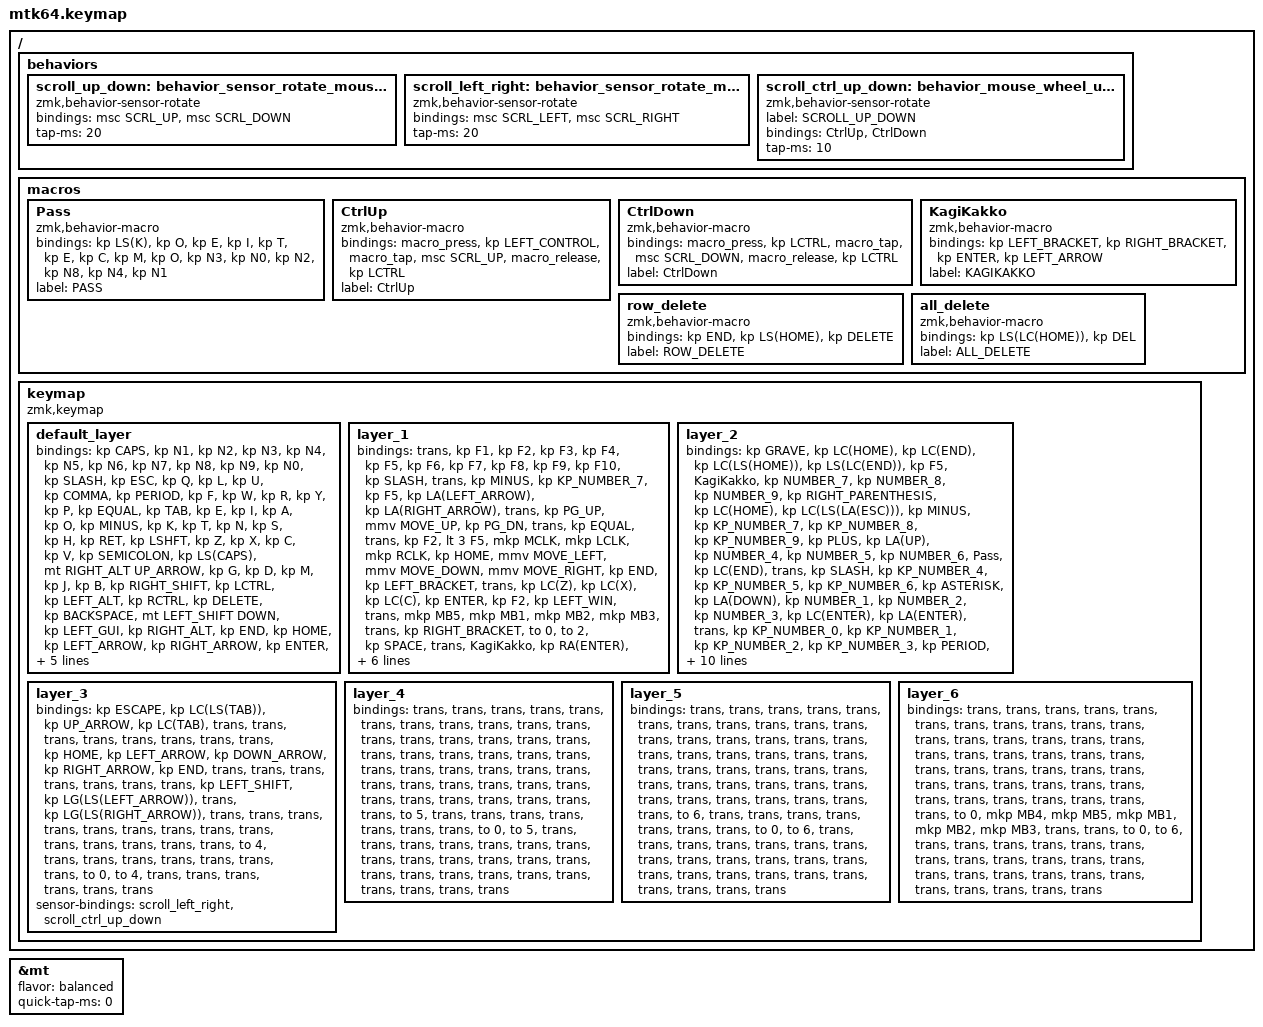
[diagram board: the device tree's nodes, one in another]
#include "keycode_japanese.h"
#include <behaviors.dtsi>
#include <dt-bindings/zmk/keys.h>
#include <dt-bindings/zmk/pointing.h>

// スクロール量の設定

#define ZMK_POINTING_DEFAULT_SCRL_VAL 100

&mt {
    flavor = "balanced";
    quick-tap-ms = <0>;
};

/ {
    behaviors {
        // 垂直スクロール用のbehaviorの設定

        scroll_up_down: behavior_sensor_rotate_mouse_wheel_up_down {
            compatible = "zmk,behavior-sensor-rotate";
            #sensor-binding-cells = <0>;
            bindings = <&msc SCRL_UP>, <&msc SCRL_DOWN>;

            tap-ms = <20>; // スクロールのタップ時間
        };

        // 水平スクロール用のbehaviorの設定

        scroll_left_right: behavior_sensor_rotate_mouse_wheel_left_right {
            compatible = "zmk,behavior-sensor-rotate";
            #sensor-binding-cells = <0>;
            bindings = <&msc SCRL_LEFT>, <&msc SCRL_RIGHT>;

            tap-ms = <20>; // スクロールのタップ時間
        };

        scroll_ctrl_up_down: behavior_mouse_wheel_up_down {
            compatible = "zmk,behavior-sensor-rotate";
            label = "SCROLL_UP_DOWN";
            #sensor-binding-cells = <0>;
            bindings = <&CtrlUp>, <&CtrlDown>;

            tap-ms = <10>;
        };
    };
};

/ {
    macros {
        Pass: Pass {
            compatible = "zmk,behavior-macro";
            #binding-cells = <0>;
            bindings = <&kp LS(K) &kp O &kp E &kp I &kp T &kp E &kp C &kp M &kp O &kp N3 &kp N0 &kp N2 &kp N8 &kp N4 &kp N1>;
            label = "PASS";
        };

        CtrlUp: CtrlUp {
            compatible = "zmk,behavior-macro";
            #binding-cells = <0>;
            bindings =
                <&macro_press>,
                <&kp LEFT_CONTROL>,
                <&macro_tap>,
                <&msc SCRL_UP>,
                <&macro_release>,
                <&kp LCTRL>;

            label = "CtrlUp";
        };

        CtrlDown: CtrlDown {
            compatible = "zmk,behavior-macro";
            #binding-cells = <0>;
            bindings =
                <&macro_press>,
                <&kp LCTRL>,
                <&macro_tap>,
                <&msc SCRL_DOWN>,
                <&macro_release>,
                <&kp LCTRL>;

            label = "CtrlDown";
        };

        KagiKakko: KagiKakko {
            compatible = "zmk,behavior-macro";
            #binding-cells = <0>;
            bindings = <&kp LEFT_BRACKET &kp RIGHT_BRACKET &kp ENTER &kp LEFT_ARROW>;
            label = "KAGIKAKKO";
        };

        row_delete: row_delete {
            compatible = "zmk,behavior-macro";
            #binding-cells = <0>;
            bindings = <&kp END &kp LS(HOME) &kp DELETE>;
            label = "ROW_DELETE";
        };

        all_delete: all_delete {
            compatible = "zmk,behavior-macro";
            #binding-cells = <0>;
            bindings = <&kp LS(LC(HOME)) &kp DEL>;
            label = "ALL_DELETE";
        };
    };

    keymap {
        compatible = "zmk,keymap";

        default_layer {
            bindings = <
&kp CAPS  &kp N1  &kp N2  &kp N3  &kp N4  &kp N5  &kp N6  &kp N7  &kp N8  &kp N9  &kp N0  &kp SLASH  &kp ESC  &kp Q  &kp L  &kp U  &kp COMMA  &kp PERIOD  &kp F  &kp W  &kp R  &kp Y  &kp P  &kp EQUAL  &kp TAB  &kp E  &kp I  &kp A  &kp O  &kp MINUS  &kp K  &kp T  &kp N  &kp S  &kp H  &kp RET  &kp LSHFT  &kp Z  &kp X  &kp C  &kp V  &kp SEMICOLON  &kp LS(CAPS)  &mt RIGHT_ALT UP_ARROW  &kp G  &kp D  &kp M  &kp J  &kp B  &kp RIGHT_SHIFT  &kp LCTRL  &kp LEFT_ALT  &kp RCTRL  &kp DELETE  &kp BACKSPACE  &mt LEFT_SHIFT DOWN  &kp LEFT_GUI  &kp RIGHT_ALT  &kp END  &kp HOME  &kp LEFT_ARROW  &kp RIGHT_ARROW  &kp ENTER  &tog 2  &lt 1 SPACE  &lt 2 BACKSPACE  &mo 1  &mo 2  &mo 3  &mo 1  &mo 2  &mo 3  &mo 1  &mo 2  &mo 3
            >;

            sensor-bindings = <&scroll_left_right>, <&scroll_up_down>;
        };

        layer_1 {
            bindings = <
&trans  &kp F1  &kp F2  &kp F3  &kp F4  &kp F5  &kp F6  &kp F7  &kp F8  &kp F9  &kp F10  &kp SLASH  &trans  &kp MINUS  &kp KP_NUMBER_7  &kp F5  &kp LA(LEFT_ARROW)  &kp LA(RIGHT_ARROW)  &trans  &kp PG_UP  &mmv MOVE_UP  &kp PG_DN  &trans  &kp EQUAL  &trans  &kp F2  &lt 3 F5  &mkp MCLK  &mkp LCLK  &mkp RCLK  &kp HOME  &mmv MOVE_LEFT  &mmv MOVE_DOWN  &mmv MOVE_RIGHT  &kp END  &kp LEFT_BRACKET  &trans  &kp LC(Z)  &kp LC(X)  &kp LC(C)  &kp ENTER  &kp F2  &kp LEFT_WIN  &trans  &mkp MB5  &mkp MB1  &mkp MB2  &mkp MB3  &trans  &kp RIGHT_BRACKET  &to 0  &to 2  &kp SPACE  &trans  &KagiKakko  &kp RA(ENTER)  &kp SQT  &kp BACKSLASH  &trans  &trans  &kp HOME  &kp END  &trans  &trans  &trans  &kp BACKSPACE  &trans  &trans  &trans  &trans  &trans  &trans  &trans  &trans  &trans
            >;

            sensor-bindings = <&inc_dec_kp D S>, <&scroll_ctrl_up_down>;
        };

        layer_2 {
            bindings = <
&kp GRAVE  &kp LC(HOME)  &kp LC(END)  &kp LC(LS(HOME))  &kp LS(LC(END))  &kp F5  &KagiKakko  &kp NUMBER_7  &kp NUMBER_8  &kp NUMBER_9  &kp RIGHT_PARENTHESIS  &kp LC(HOME)  &kp LC(LS(LA(ESC)))  &kp MINUS  &kp KP_NUMBER_7  &kp KP_NUMBER_8  &kp KP_NUMBER_9  &kp PLUS  &kp LA(UP)  &kp NUMBER_4  &kp NUMBER_5  &kp NUMBER_6  &Pass  &kp LC(END)  &trans  &kp SLASH  &kp KP_NUMBER_4  &kp KP_NUMBER_5  &kp KP_NUMBER_6  &kp ASTERISK  &kp LA(DOWN)  &kp NUMBER_1  &kp NUMBER_2  &kp NUMBER_3  &kp LC(ENTER)  &kp LA(ENTER)  &trans  &kp KP_NUMBER_0  &kp KP_NUMBER_1  &kp KP_NUMBER_2  &kp KP_NUMBER_3  &kp PERIOD  &to 3  &trans  &kp F4  &kp NUMBER_0  &mkp MB2  &mkp MB3  &trans  &kp LC(LS(HOME))  &to 0  &to 3  &all_delete  &row_delete  &trans  &trans  &kp APOS  &kp LC(LS(END))  &trans  &kp F2  &kp HOME  &kp END  &trans  &trans  &kp LEFT_SHIFT  &trans  &trans  &trans  &trans  &trans  &trans  &trans  &trans  &trans  &trans
            >;

            sensor-bindings =
                <&inc_dec_kp LEFT_ARROW RIGHT_ARROW>,
                <&inc_dec_kp UP_ARROW DOWN_ARROW>;
        };

        layer_3 {
            bindings = <
&kp ESCAPE  &kp LC(LS(TAB))  &kp UP_ARROW  &kp LC(TAB)  &trans  &trans  &trans  &trans  &trans  &trans  &trans  &trans  &kp HOME  &kp LEFT_ARROW  &kp DOWN_ARROW  &kp RIGHT_ARROW  &kp END  &trans  &trans  &trans  &trans  &trans  &trans  &trans  &kp LEFT_SHIFT  &kp LG(LS(LEFT_ARROW))  &trans  &kp LG(LS(RIGHT_ARROW))  &trans  &trans  &trans  &trans  &trans  &trans  &trans  &trans  &trans  &trans  &trans  &trans  &trans  &trans  &to 4  &trans  &trans  &trans  &trans  &trans  &trans  &trans  &to 0  &to 4  &trans  &trans  &trans  &trans  &trans  &trans
            >;

            sensor-bindings = <&scroll_left_right>, <&scroll_ctrl_up_down>;
        };

        layer_4 {
            bindings = <
&trans  &trans  &trans  &trans  &trans  &trans  &trans  &trans  &trans  &trans  &trans  &trans  &trans  &trans  &trans  &trans  &trans  &trans  &trans  &trans  &trans  &trans  &trans  &trans  &trans  &trans  &trans  &trans  &trans  &trans  &trans  &trans  &trans  &trans  &trans  &trans  &trans  &trans  &trans  &trans  &trans  &trans  &to 5  &trans  &trans  &trans  &trans  &trans  &trans  &trans  &to 0  &to 5  &trans  &trans  &trans  &trans  &trans  &trans  &trans  &trans  &trans  &trans  &trans  &trans  &trans  &trans  &trans  &trans  &trans  &trans  &trans  &trans  &trans  &trans  &trans
            >;
        };

        layer_5 {
            bindings = <
&trans  &trans  &trans  &trans  &trans  &trans  &trans  &trans  &trans  &trans  &trans  &trans  &trans  &trans  &trans  &trans  &trans  &trans  &trans  &trans  &trans  &trans  &trans  &trans  &trans  &trans  &trans  &trans  &trans  &trans  &trans  &trans  &trans  &trans  &trans  &trans  &trans  &trans  &trans  &trans  &trans  &trans  &to 6  &trans  &trans  &trans  &trans  &trans  &trans  &trans  &to 0  &to 6  &trans  &trans  &trans  &trans  &trans  &trans  &trans  &trans  &trans  &trans  &trans  &trans  &trans  &trans  &trans  &trans  &trans  &trans  &trans  &trans  &trans  &trans  &trans
            >;
        };

        layer_6 {
            bindings = <
&trans  &trans  &trans  &trans  &trans  &trans  &trans  &trans  &trans  &trans  &trans  &trans  &trans  &trans  &trans  &trans  &trans  &trans  &trans  &trans  &trans  &trans  &trans  &trans  &trans  &trans  &trans  &trans  &trans  &trans  &trans  &trans  &trans  &trans  &trans  &trans  &trans  &trans  &trans  &trans  &trans  &trans  &to 0  &mkp MB4  &mkp MB5  &mkp MB1  &mkp MB2  &mkp MB3  &trans  &trans  &to 0  &to 6  &trans  &trans  &trans  &trans  &trans  &trans  &trans  &trans  &trans  &trans  &trans  &trans  &trans  &trans  &trans  &trans  &trans  &trans  &trans  &trans  &trans  &trans  &trans
            >;
        };
    };
};
